# PY32F403xx register map
Vendor: PUYA Co.Ltd; Series: ARMCM4; File version: 1.2
CPU: CM4 r0p1, little endian, MPU, FPU, 4 interrupt priority bits
Registers are 32-bit, read-write, reset 0x0 unless marked. A register's access mark holds for its fields unless they carry their own. Offsets are from the block's base; [hi:lo] are bit positions; {n}, {i} and the like mark numbered series; 'fields as' and 'values as' point back to an identical list.

## DBGMCU
Base 0xE0042000
0x00 IDCODE
  [31:0] REV_ID ro
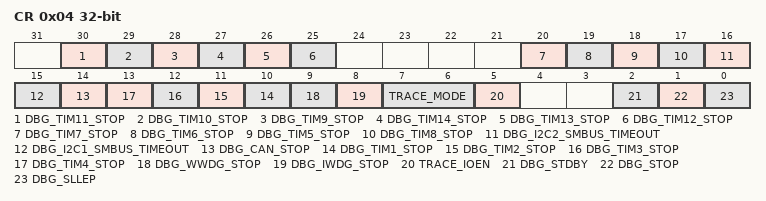
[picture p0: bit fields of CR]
0x04 CR
  [30] DBG_TIM11_STOP, [29] DBG_TIM10_STOP, [28] DBG_TIM9_STOP, [27] DBG_TIM14_STOP, [26] DBG_TIM13_STOP, [25] DBG_TIM12_STOP, [20] DBG_TIM7_STOP, [19] DBG_TIM6_STOP, [18] DBG_TIM5_STOP, [17] DBG_TIM8_STOP, [16] DBG_I2C2_SMBUS_TIMEOUT, [15] DBG_I2C1_SMBUS_TIMEOUT, [14] DBG_CAN_STOP, [n+9] DBG_TIM{n}_STOP (n=1..4), [9] DBG_WWDG_STOP, [8] DBG_IWDG_STOP, [7:6] TRACE_MODE, [5] TRACE_IOEN, [2] DBG_STDBY, [1] DBG_STOP, [0] DBG_SLLEP

## DMA1 — desc DMA
Base 0x40020000
Same registers: DMA2 0x40020400
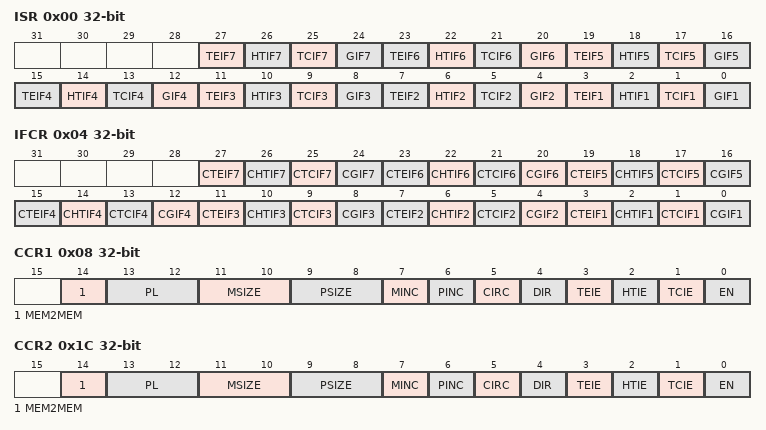
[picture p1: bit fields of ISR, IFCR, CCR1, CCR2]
0x00 ISR
  [4n-1] TEIF{n} ro (n=1..7), [4n-2] HTIF{n} ro (n=1..7), [4n-3] TCIF{n} ro (n=1..7), [4n-4] GIF{n} ro (n=1..7)
0x04 IFCR
  [4n-1] CTEIF{n} (n=1..7), [4n-2] CHTIF{n} (n=1..7), [4n-3] CTCIF{n} (n=1..7), [4n-4] CGIF{n} (n=1..7)
0x08 CCR1
  [14] MEM2MEM, [13:12] PL, [11:10] MSIZE, [9:8] PSIZE, [7] MINC, [6] PINC, [5] CIRC, [4] DIR, [3] TEIE, [2] HTIE, [1] TCIE, [0] EN
0x0C CNDTR1
  [15:0] NDT
0x10 CPAR1
  [31:0] PA
{0x0+0x14*i} CMAR{i} (i=1..7)
  [31:0] MA
0x1C CCR2
  fields as CCR1
0x20 CNDTR2
  [15:0] NDT
0x24 CPAR2
  [31:0] PA
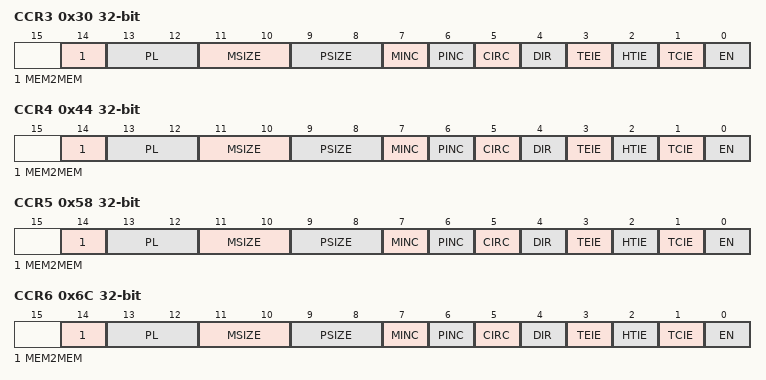
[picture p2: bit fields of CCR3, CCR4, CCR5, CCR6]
0x30 CCR3
  fields as CCR1
0x34 CNDTR3
  [15:0] NDT
0x38 CPAR3
  [31:0] PA
0x44 CCR4
  fields as CCR1
0x48 CNDTR4
  [15:0] NDT
0x4C CPAR4
  [31:0] PA
0x58 CCR5
  fields as CCR1
0x5C CNDTR5
  [15:0] NDT
0x60 CPAR5
  [31:0] PA
0x6C CCR6
  fields as CCR1
0x70 CNDTR6
  [15:0] NDT
0x74 CPAR6
  [31:0] PA
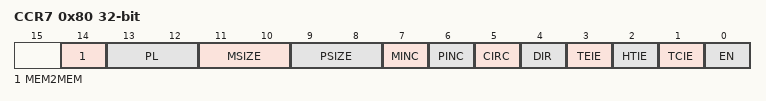
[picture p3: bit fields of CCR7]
0x80 CCR7
  fields as CCR1
0x84 CNDTR7
  [15:0] NDT
0x88 CPAR7
  [31:0] PA

## ESMC
Base 0xA0001000
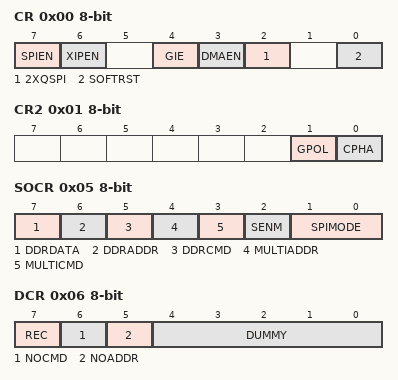
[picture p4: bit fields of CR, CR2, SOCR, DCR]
0x00 CR 8-bit
  [7] SPIEN, [6] XIPEN, [4] GIE, [3] DMAEN, [2] 2XQSPI, [0] SOFTRST
0x01 CR2 8-bit
  [1] GPOL — desc CPOL
  [0] CPHA
0x02 TCR 8-bit
0x03 BAUD 8-bit
0x04 SFCR 8-bit
  [7:0] INS0
0x05 SOCR 8-bit
  [7] DDRDATA, [6] DDRADDR, [5] DDRCMD, [4] MULTIADDR, [3] MULTICMD, [2] SENM, [1:0] SPIMODE
0x06 DCR 8-bit
  [7] REC, [6] NOCMD, [5] NOADDR, [4:0] DUMMY
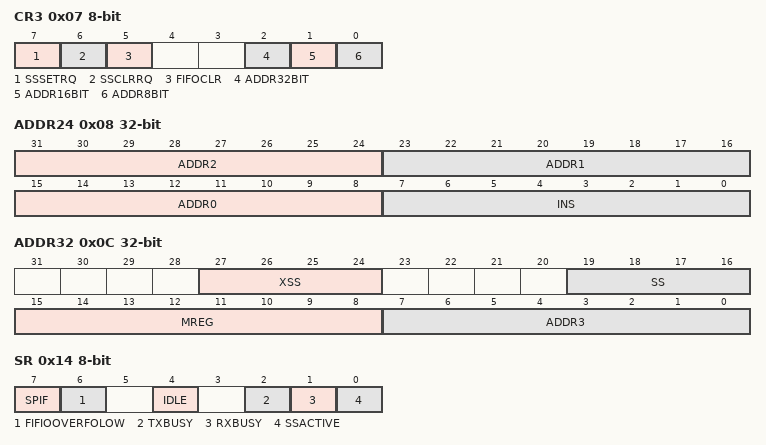
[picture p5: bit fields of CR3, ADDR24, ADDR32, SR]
0x07 CR3 8-bit
  [7] SSSETRQ, [6] SSCLRRQ, [5] FIFOCLR, [2] ADDR32BIT, [1] ADDR16BIT, [0] ADDR8BIT
0x08 ADDR24
  [31:24] ADDR2, [23:16] ADDR1, [15:8] ADDR0, [7:0] INS
0x0C ADDR32
  [27:24] XSS, [19:16] SS, [15:8] MREG, [7:0] ADDR3
0x14 SR 8-bit
  [7] SPIF, [6] FIFIOOVERFOLOW, [4] IDLE, [2] TXBUSY, [1] RXBUSY, [0] SSACTIVE
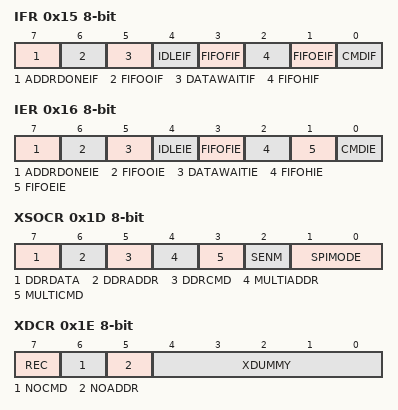
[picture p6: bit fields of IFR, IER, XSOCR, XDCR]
0x15 IFR 8-bit
  [7] ADDRDONEIF, [6] FIFOOIF, [5] DATAWAITIF, [4] IDLEIF, [3] FIFOFIF, [2] FIFOHIF, [1] FIFOEIF, [0] CMDIF
0x16 IER 8-bit
  [7] ADDRDONEIE, [6] FIFOOIE, [5] DATAWAITIE, [4] IDLEIE, [3] FIFOFIE, [2] FIFOHIE, [1] FIFOEIE, [0] CMDIE
0x1C XSFCR 8-bit
  [7:0] XINS
0x1D XSOCR 8-bit
  fields as SOCR
0x1E XDCR 8-bit — desc DCR
  [7] REC, [6] NOCMD, [5] NOADDR, [4:0] XDUMMY
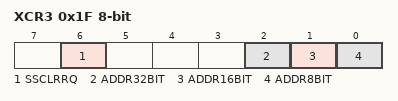
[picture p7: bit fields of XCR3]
0x1F XCR3 8-bit
  [6] SSCLRRQ, [2] ADDR32BIT, [1] ADDR16BIT, [0] ADDR8BIT

## EXTI
Base 0x40010400
0x00 IMR
  [18:0] MR
0x04 EMR
  [18:0] MR
0x08 RTSR
  [18:0] TR
0x0C FTSR
  [18:0] TR
0x10 SWIER
  [18:0] SWIER
0x14 PR
  [18:0] PR

## FLASH
Base 0x40022000
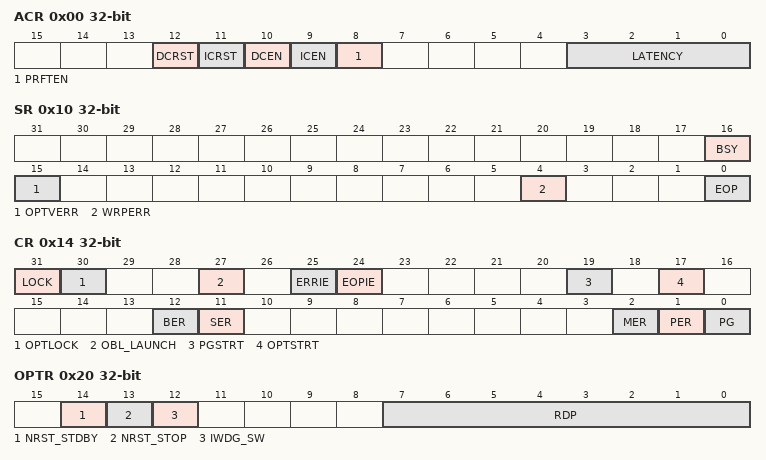
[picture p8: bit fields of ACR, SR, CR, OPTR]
0x00 ACR
  [12] DCRST, [11] ICRST, [10] DCEN, [9] ICEN, [8] PRFTEN, [3:0] LATENCY
0x08 KEYR
  [31:0] KEY
0x0C OPTKEYR
  [31:0] OPTKEY
0x10 SR
  [16] BSY ro, [15] OPTVERR, [4] WRPERR, [0] EOP
0x14 CR
  [31] LOCK, [30] OPTLOCK, [27] OBL_LAUNCH, [25] ERRIE, [24] EOPIE, [19] PGSTRT, [17] OPTSTRT, [12] BER, [11] SER, [2] MER, [1] PER, [0] PG
0x20 OPTR
  [14] NRST_STDBY, [13] NRST_STOP, [12] IWDG_SW, [7:0] RDP
0x2C WRPR
  [11:0] WRP

## GPIOA — desc GPIO
Base 0x48000000
Same registers: GPIOB 0x48000400, GPIOC 0x48000800, GPIOD 0x48000C00, GPIOE 0x48001000
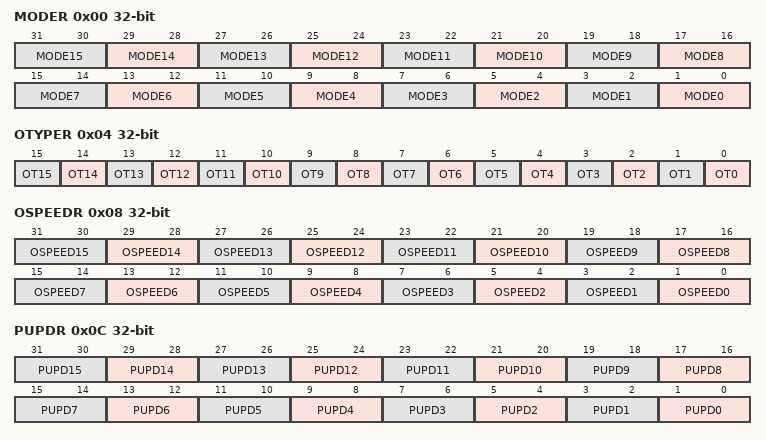
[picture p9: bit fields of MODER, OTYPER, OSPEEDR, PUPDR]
0x00 MODER
  [2n+1:2n] MODE{n} (n=0..15)
0x04 OTYPER
  [n] OT{n} (n=0..15)
0x08 OSPEEDR
  [2n+1:2n] OSPEED{n} (n=0..15)
0x0C PUPDR
  [2n+1:2n] PUPD{n} (n=0..15)
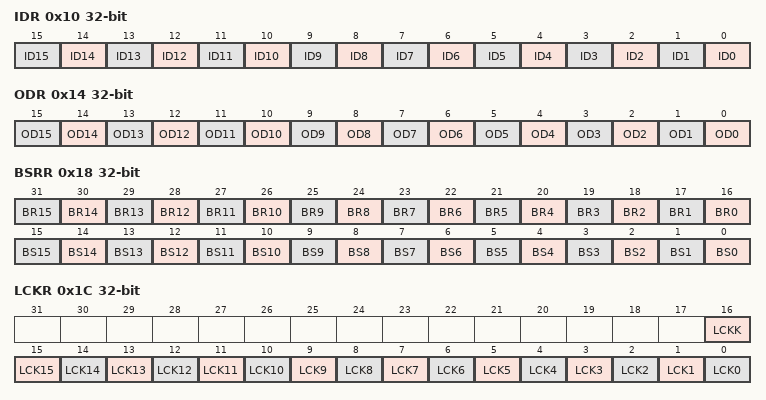
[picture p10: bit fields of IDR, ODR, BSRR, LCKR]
0x10 IDR
  [n] ID{n} ro (n=0..15)
0x14 ODR
  [n] OD{n} (n=0..15)
0x18 BSRR
  [n+16] BR{n} (n=0..15), [n] BS{n} (n=0..15)
0x1C LCKR
  [16] LCKK, [n] LCK{n} (n=0..15)
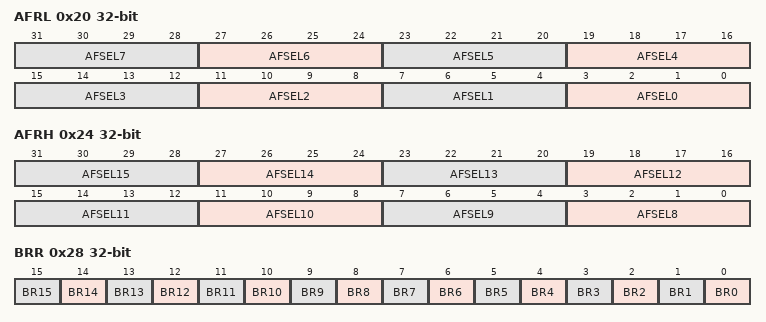
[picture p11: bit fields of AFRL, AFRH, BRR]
0x20 AFRL
  [4n+3:4n] AFSEL{n} (n=0..7)
0x24 AFRH
  [4n-29:4n-32] AFSEL{n} (n=8..15)
0x28 BRR
  [n] BR{n} (n=0..15)
